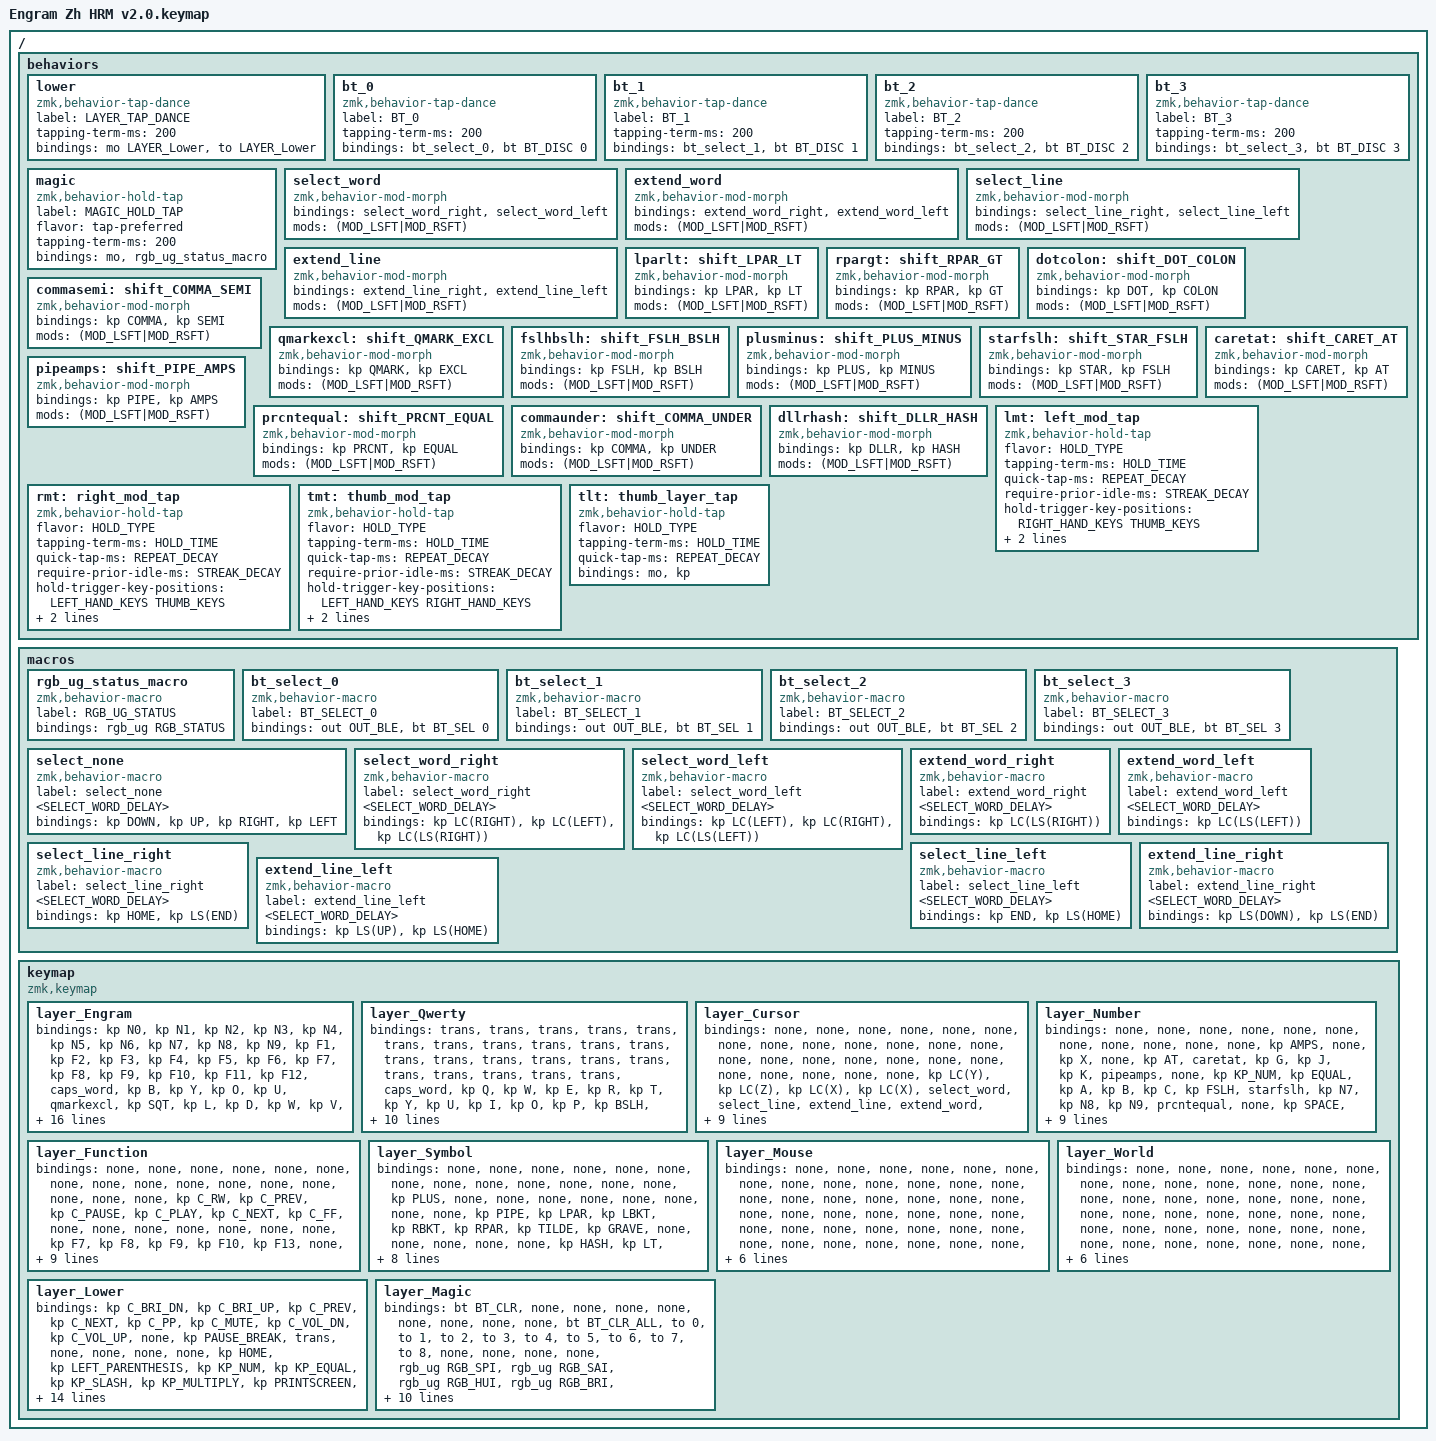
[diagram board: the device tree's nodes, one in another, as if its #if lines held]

/*
 * Copyright (c) 2020 The ZMK Contributors
 * Copyright (c) 2023 Innaworks Development Limited, trading as MoErgo
 *
 * SPDX-License-Identifier: MIT
 */


/* THIS FILE WAS GENERATED BY GLOVE80 LAYOUT EDITOR
 *
 * This file was generated automatically. You may or may not want to
 * edit it directly.
 */

#include <behaviors.dtsi>
/* Include all behavior includes needed */
#include <dt-bindings/zmk/outputs.h>
#include <dt-bindings/zmk/keys.h>
#include <dt-bindings/zmk/bt.h>
#include <dt-bindings/zmk/rgb.h>

/* Automatically generated layer name #define */
#define LAYER_Engram 0
#define LAYER_Qwerty 1
#define LAYER_Cursor 2
#define LAYER_Number 3
#define LAYER_Function 4
#define LAYER_Symbol 5
#define LAYER_Mouse 6
#define LAYER_World 7
#define LAYER_Lower 8
#define LAYER_Magic 9

/* To deal with the situation where there is no Lower layer, to keep &lower happy */
#ifndef LAYER_Lower
#define LAYER_Lower 0
#endif

/* Custom Device-tree */



/* Glove80 system behavior & macros */
/ {
    behaviors {
        // For the "layer" key, it'd nice to be able to use it as either a shift or a toggle.
        // Configure it as a tap dance, so the first tap (or hold) is a &mo and the second tap is a &to
        lower: lower {
            compatible = "zmk,behavior-tap-dance";
            label = "LAYER_TAP_DANCE";
            #binding-cells = <0>;
            tapping-term-ms = <200>;
            bindings = <&mo LAYER_Lower>, <&to LAYER_Lower>;
        };
    };
};

/ {
    macros {
        rgb_ug_status_macro: rgb_ug_status_macro {
            label = "RGB_UG_STATUS";
            compatible = "zmk,behavior-macro";
            #binding-cells = <0>;
            bindings
                = <&rgb_ug RGB_STATUS>;
        };
    };
};


/ {
#ifdef BT_DISC_CMD
    behaviors {
        bt_0: bt_0 {
            compatible = "zmk,behavior-tap-dance";
            label = "BT_0";
            #binding-cells = <0>;
            tapping-term-ms = <200>;
            bindings = <&bt_select_0>, <&bt BT_DISC 0>;
        };
        bt_1: bt_1 {
            compatible = "zmk,behavior-tap-dance";
            label = "BT_1";
            #binding-cells = <0>;
            tapping-term-ms = <200>;
            bindings = <&bt_select_1>, <&bt BT_DISC 1>;
        };
        bt_2: bt_2 {
            compatible = "zmk,behavior-tap-dance";
            label = "BT_2";
            #binding-cells = <0>;
            tapping-term-ms = <200>;
            bindings = <&bt_select_2>, <&bt BT_DISC 2>;
        };
        bt_3: bt_3 {
            compatible = "zmk,behavior-tap-dance";
            label = "BT_3";
            #binding-cells = <0>;
            tapping-term-ms = <200>;
            bindings = <&bt_select_3>, <&bt BT_DISC 3>;
        };
    };
    macros {
        bt_select_0: bt_select_0 {
            label = "BT_SELECT_0";
            compatible = "zmk,behavior-macro";
            #binding-cells = <0>;
            bindings
                = <&out OUT_BLE>,
                  <&bt BT_SEL 0>;
        };
        bt_select_1: bt_select_1 {
            label = "BT_SELECT_1";
            compatible = "zmk,behavior-macro";
            #binding-cells = <0>;
            bindings
                = <&out OUT_BLE>,
                  <&bt BT_SEL 1>;
        };
        bt_select_2: bt_select_2 {
            label = "BT_SELECT_2";
            compatible = "zmk,behavior-macro";
            #binding-cells = <0>;
            bindings
                = <&out OUT_BLE>,
                  <&bt BT_SEL 2>;
        };
        bt_select_3: bt_select_3 {
            label = "BT_SELECT_3";
            compatible = "zmk,behavior-macro";
            #binding-cells = <0>;
            bindings
                = <&out OUT_BLE>,
                  <&bt BT_SEL 3>;
        };
    };
#else
    macros {
        bt_0: bt_0 {
            label = "BT_0";
            compatible = "zmk,behavior-macro";
            #binding-cells = <0>;
            bindings
                = <&out OUT_BLE>,
                  <&bt BT_SEL 0>;
        };
        bt_1: bt_1 {
            label = "BT_1";
            compatible = "zmk,behavior-macro";
            #binding-cells = <0>;
            bindings
                = <&out OUT_BLE>,
                  <&bt BT_SEL 1>;
        };
        bt_2: bt_2 {
            label = "BT_2";
            compatible = "zmk,behavior-macro";
            #binding-cells = <0>;
            bindings
                = <&out OUT_BLE>,
                  <&bt BT_SEL 2>;
        };
        bt_3: bt_3 {
            label = "BT_3";
            compatible = "zmk,behavior-macro";
            #binding-cells = <0>;
            bindings
                = <&out OUT_BLE>,
                  <&bt BT_SEL 3>;
        };
    };
#endif
};

/ {
    behaviors {
        magic: magic {
            compatible = "zmk,behavior-hold-tap";
            label = "MAGIC_HOLD_TAP";
            #binding-cells = <2>;
            flavor = "tap-preferred";
            tapping-term-ms = <200>;
            bindings = <&mo>, <&rgb_ug_status_macro>;
        };
    };
};

/* #define for key positions */
#define POS_LH_T1 52
#define POS_LH_T2 53
#define POS_LH_T3 54
#define POS_LH_T4 69
#define POS_LH_T5 70
#define POS_LH_T6 71
#define POS_LH_C1R2 15
#define POS_LH_C1R3 27
#define POS_LH_C1R4 39
#define POS_LH_C1R5 51
#define POS_LH_C2R1 4
#define POS_LH_C2R2 14
#define POS_LH_C2R3 26
#define POS_LH_C2R4 38
#define POS_LH_C2R5 50
#define POS_LH_C2R6 68
#define POS_LH_C3R1 3
#define POS_LH_C3R2 13
#define POS_LH_C3R3 25
#define POS_LH_C3R4 37
#define POS_LH_C3R5 49
#define POS_LH_C3R6 67
#define POS_LH_C4R1 2
#define POS_LH_C4R2 12
#define POS_LH_C4R3 24
#define POS_LH_C4R4 36
#define POS_LH_C4R5 48
#define POS_LH_C4R6 66
#define POS_LH_C5R1 1
#define POS_LH_C5R2 11
#define POS_LH_C5R3 23
#define POS_LH_C5R4 35
#define POS_LH_C5R5 47
#define POS_LH_C5R6 65
#define POS_LH_C6R1 0
#define POS_LH_C6R2 10
#define POS_LH_C6R3 22
#define POS_LH_C6R4 34
#define POS_LH_C6R5 46
#define POS_LH_C6R6 64
#define POS_RH_T1 57
#define POS_RH_T2 56
#define POS_RH_T3 55
#define POS_RH_T4 74
#define POS_RH_T5 73
#define POS_RH_T6 72
#define POS_RH_C1R2 16
#define POS_RH_C1R3 28
#define POS_RH_C1R4 40
#define POS_RH_C1R5 58
#define POS_RH_C2R1 5
#define POS_RH_C2R2 17
#define POS_RH_C2R3 29
#define POS_RH_C2R4 41
#define POS_RH_C2R5 59
#define POS_RH_C2R6 75
#define POS_RH_C3R1 6
#define POS_RH_C3R2 18
#define POS_RH_C3R3 30
#define POS_RH_C3R4 42
#define POS_RH_C3R5 60
#define POS_RH_C3R6 76
#define POS_RH_C4R1 7
#define POS_RH_C4R2 19
#define POS_RH_C4R3 31
#define POS_RH_C4R4 43
#define POS_RH_C4R5 61
#define POS_RH_C4R6 77
#define POS_RH_C5R1 8
#define POS_RH_C5R2 20
#define POS_RH_C5R3 32
#define POS_RH_C5R4 44
#define POS_RH_C5R5 62
#define POS_RH_C5R6 78
#define POS_RH_C6R1 9
#define POS_RH_C6R2 21
#define POS_RH_C6R3 33
#define POS_RH_C6R4 45
#define POS_RH_C6R5 63
#define POS_RH_C6R6 79

/* Custom Defined Behaviors */
/ {
// HRM parameters
#define HOLD_TYPE "tap-preferred" // flavor of hold-tap. `tap-preferred` means modifier will only be triggered if held for `HOLD_TIME` or longer. Pressing another key before this triggers 'tap' behavior. Except for keys in `hold-trigger-key-positions`
#define HOLD_TIME 200 // how long you need to hold key in order to send their modifiers to the computer
#define STREAK_DECAY 150 // how long you need to wait after typing before you can use home row mods again.
#define REPEAT_DECAY 300 // how much time you have left after tapping a key to hold it again in order to make it auto-repeat.
#define SELECT_WORD_DELAY 1 // wait-ms and tap-ms for select word macros

// Glove80 key positions index for positional hold-tap
    #define LEFT_HAND_KEYS      \
          0  1  2  3  4         \
         10 11 12 13 14 15      \
         22 23 24 25 26 27      \
         34 35 36 37 38 39      \
         46 47 48 49 50 51      \
         64 65 66 67 68
    #define RIGHT_HAND_KEYS     \
                                           5  6  7  8  9 \
                                       16 17 18 19 20 21 \
                                       28 29 30 31 32 33 \
                                       40 41 42 43 44 45 \
                                       58 59 60 61 62 63 \
                                          75 76 77 78 79
    #define THUMB_KEYS          \
                        69 52       57 74                \
                         70 53     56 73                 \
                          71 54   55 72

macros {

    select_none: select_none {
      label = "select_none";
      compatible = "zmk,behavior-macro";
      #binding-cells = <0>;
      wait-ms: <SELECT_WORD_DELAY>;
      tap-ms: <SELECT_WORD_DELAY>;
      bindings = <&kp DOWN &kp UP &kp RIGHT &kp LEFT>;
    };

    select_word_right: select_word_right {
      label = "select_word_right";
      compatible = "zmk,behavior-macro";
      #binding-cells = <0>;
      wait-ms: <SELECT_WORD_DELAY>;
      tap-ms: <SELECT_WORD_DELAY>;
      bindings = <&kp LC(RIGHT) &kp LC(LEFT) &kp LC(LS(RIGHT))>;
    };

    select_word_left: select_word_left {
      label = "select_word_left";
      compatible = "zmk,behavior-macro";
      #binding-cells = <0>;
      wait-ms: <SELECT_WORD_DELAY>;
      tap-ms: <SELECT_WORD_DELAY>;
      bindings = <&kp LC(LEFT) &kp LC(RIGHT) &kp LC(LS(LEFT))>;
    };

    extend_word_right: extend_word_right {
      label = "extend_word_right";
      compatible = "zmk,behavior-macro";
      #binding-cells = <0>;
      wait-ms: <SELECT_WORD_DELAY>;
      tap-ms: <SELECT_WORD_DELAY>;
      bindings = <&kp LC(LS(RIGHT))>;
    };

    extend_word_left: extend_word_left {
      label = "extend_word_left";
      compatible = "zmk,behavior-macro";
      #binding-cells = <0>;
      wait-ms: <SELECT_WORD_DELAY>;
      tap-ms: <SELECT_WORD_DELAY>;
      bindings = <&kp LC(LS(LEFT))>;
    };

    select_line_right: select_line_right {
      label = "select_line_right";
      compatible = "zmk,behavior-macro";
      #binding-cells = <0>;
      wait-ms: <SELECT_WORD_DELAY>;
      tap-ms: <SELECT_WORD_DELAY>;
      bindings = <&kp HOME &kp LS(END)>;
    };

    select_line_left: select_line_left {
      label = "select_line_left";
      compatible = "zmk,behavior-macro";
      #binding-cells = <0>;
      wait-ms: <SELECT_WORD_DELAY>;
      tap-ms: <SELECT_WORD_DELAY>;
      bindings = <&kp END &kp LS(HOME)>;
    };

    extend_line_right: extend_line_right {
      label = "extend_line_right";
      compatible = "zmk,behavior-macro";
      #binding-cells = <0>;
      wait-ms: <SELECT_WORD_DELAY>;
      tap-ms: <SELECT_WORD_DELAY>;
      bindings = <&kp LS(DOWN) &kp LS(END)>;
    };

    extend_line_left: extend_line_left {
      label = "extend_line_left";
      compatible = "zmk,behavior-macro";
      #binding-cells = <0>;
      wait-ms: <SELECT_WORD_DELAY>;
      tap-ms: <SELECT_WORD_DELAY>;
      bindings = <&kp LS(UP) &kp LS(HOME)>;
    };

};

behaviors {
    select_word: select_word {
      compatible = "zmk,behavior-mod-morph";
      #binding-cells = <0>;
      bindings = <&select_word_right>, <&select_word_left>;
      mods = <(MOD_LSFT|MOD_RSFT)>;
    };

    extend_word: extend_word {
      compatible = "zmk,behavior-mod-morph";
      #binding-cells = <0>;
      bindings = <&extend_word_right>, <&extend_word_left>;
      mods = <(MOD_LSFT|MOD_RSFT)>;
    };

    select_line: select_line {
      compatible = "zmk,behavior-mod-morph";
      #binding-cells = <0>;
      bindings = <&select_line_right>, <&select_line_left>;
      mods = <(MOD_LSFT|MOD_RSFT)>;
    };

    extend_line: extend_line {
      compatible = "zmk,behavior-mod-morph";
      #binding-cells = <0>;
      bindings = <&extend_line_right>, <&extend_line_left>;
      mods = <(MOD_LSFT|MOD_RSFT)>;
    };

    lparlt: shift_LPAR_LT {
      compatible = "zmk,behavior-mod-morph";
      #binding-cells = <0>;
      bindings = <&kp LPAR>, <&kp LT>;
      mods = <(MOD_LSFT|MOD_RSFT)>;
    };

    rpargt: shift_RPAR_GT {
      compatible = "zmk,behavior-mod-morph";
      #binding-cells = <0>;
      bindings = <&kp RPAR>, <&kp GT>;
      mods = <(MOD_LSFT|MOD_RSFT)>;
    };

    dotcolon: shift_DOT_COLON {
      compatible = "zmk,behavior-mod-morph";
      #binding-cells = <0>;
      bindings = <&kp DOT>, <&kp COLON>;
      mods = <(MOD_LSFT|MOD_RSFT)>;
    };

    commasemi: shift_COMMA_SEMI {
      compatible = "zmk,behavior-mod-morph";
      #binding-cells = <0>;
      bindings = <&kp COMMA>, <&kp SEMI>;
      mods = <(MOD_LSFT|MOD_RSFT)>;
    };

    qmarkexcl: shift_QMARK_EXCL {
      compatible = "zmk,behavior-mod-morph";
      #binding-cells = <0>;
      bindings = <&kp QMARK>, <&kp EXCL>;
      mods = <(MOD_LSFT|MOD_RSFT)>;
    };

    fslhbslh: shift_FSLH_BSLH {
      compatible = "zmk,behavior-mod-morph";
      #binding-cells = <0>;
      bindings = <&kp FSLH>, <&kp BSLH>;
      mods = <(MOD_LSFT|MOD_RSFT)>;
    };

    plusminus: shift_PLUS_MINUS {
      compatible = "zmk,behavior-mod-morph";
      #binding-cells = <0>;
      bindings = <&kp PLUS>, <&kp MINUS>;
      mods = <(MOD_LSFT|MOD_RSFT)>;
    };

    starfslh: shift_STAR_FSLH {
      compatible = "zmk,behavior-mod-morph";
      #binding-cells = <0>;
      bindings = <&kp STAR>, <&kp FSLH>;
      mods = <(MOD_LSFT|MOD_RSFT)>;
    };

    caretat: shift_CARET_AT {
      compatible = "zmk,behavior-mod-morph";
      #binding-cells = <0>;
      bindings = <&kp CARET>, <&kp AT>;
      mods = <(MOD_LSFT|MOD_RSFT)>;
    };

    pipeamps: shift_PIPE_AMPS {
      compatible = "zmk,behavior-mod-morph";
      #binding-cells = <0>;
      bindings = <&kp PIPE>, <&kp AMPS>;
      mods = <(MOD_LSFT|MOD_RSFT)>;
    };

    prcntequal: shift_PRCNT_EQUAL {
      compatible = "zmk,behavior-mod-morph";
      #binding-cells = <0>;
      bindings = <&kp PRCNT>, <&kp EQUAL>;
      mods = <(MOD_LSFT|MOD_RSFT)>;
    };

    commaunder: shift_COMMA_UNDER {
      compatible = "zmk,behavior-mod-morph";
      #binding-cells = <0>;
      bindings = <&kp COMMA>, <&kp UNDER>;
      mods = <(MOD_LSFT|MOD_RSFT)>;
    };

    dllrhash: shift_DLLR_HASH {
      compatible = "zmk,behavior-mod-morph";
      #binding-cells = <0>;
      bindings = <&kp DLLR>, <&kp HASH>;
      mods = <(MOD_LSFT|MOD_RSFT)>;
    };

    lmt: left_mod_tap {
      compatible = "zmk,behavior-hold-tap";
      flavor = HOLD_TYPE;
      tapping-term-ms = <HOLD_TIME>;
      quick-tap-ms = <REPEAT_DECAY>;
      require-prior-idle-ms = <STREAK_DECAY>;
      hold-trigger-key-positions = <RIGHT_HAND_KEYS THUMB_KEYS>;
      hold-trigger-on-release; // wait for other home row mods
      #binding-cells = <2>;
      bindings = <&kp>, <&kp>;
    };

    rmt: right_mod_tap {
      compatible = "zmk,behavior-hold-tap";
      flavor = HOLD_TYPE;
      tapping-term-ms = <HOLD_TIME>;
      quick-tap-ms = <REPEAT_DECAY>;
      require-prior-idle-ms = <STREAK_DECAY>;
      hold-trigger-key-positions = <LEFT_HAND_KEYS THUMB_KEYS>;
      hold-trigger-on-release; // wait for other home row mods
      #binding-cells = <2>;
      bindings = <&kp>, <&kp>;
    };

    tmt: thumb_mod_tap {
      compatible = "zmk,behavior-hold-tap";
      flavor = HOLD_TYPE;
      tapping-term-ms = <HOLD_TIME>;
      quick-tap-ms = <REPEAT_DECAY>;
      require-prior-idle-ms = <STREAK_DECAY>;
      hold-trigger-key-positions = <LEFT_HAND_KEYS RIGHT_HAND_KEYS>;
      hold-trigger-on-release; // wait for other home row mods
      #binding-cells = <2>;
      bindings = <&kp>, <&kp>;
    };

    tlt: thumb_layer_tap {
      compatible = "zmk,behavior-hold-tap";
      flavor = HOLD_TYPE;
      tapping-term-ms = <HOLD_TIME>;
      quick-tap-ms = <REPEAT_DECAY>;
      #binding-cells = <2>;
      bindings = <&mo>, <&kp>;
    };

};
};

/* Automatically generated macro definitions */
/ {
    macros {
    
    };
};

/* Automatically generated keymap */
/ {
    keymap {
        compatible = "zmk,keymap";


        layer_Engram {
            bindings = <
               &kp N0       &kp N1       &kp N2        &kp N3                  &kp N4                                                                                                                                                                              &kp N5        &kp N6       &kp N7       &kp N8                &kp N9
               &kp F1       &kp F2       &kp F3        &kp F4                  &kp F5      &kp F6                                                                                                                                                    &kp F7        &kp F8        &kp F9      &kp F10      &kp F11               &kp F12
           &caps_word        &kp B        &kp Y         &kp O                   &kp U  &qmarkexcl                                                                                                                                                   &kp SQT         &kp L         &kp D        &kp W        &kp V              &kp CAPS
                &kp Z  &lmt LGUI C  &lmt LALT I  &lmt LCTRL E            &lmt LSHFT A  &commasemi                                                                                                                                                 &dotcolon  &rmt LSHFT H  &rmt LCTRL T  &rmt LALT S  &rmt LGUI N                 &kp Q
            &kp LSHFT        &kp G        &kp X         &kp J                   &kp K   &fslhbslh        &tmt LCTRL SPACE        &tmt LALT ENTER            &tmt LGUI TAB         &tmt RGUI ESC          &tmt RALT BSPC           &tmt RCTRL DEL  &kp MINUS         &kp R         &kp M        &kp F        &kp P        &mt RSHFT CAPS
 &magic LAYER_Magic 0     &kp LEFT       &kp UP      &kp DOWN  &tlt LAYER_Lower RIGHT              &tlt LAYER_Cursor BSPC  &tlt LAYER_Number DEL  &tlt LAYER_Function ESC  &tlt LAYER_World TAB  &tlt LAYER_Mouse ENTER  &tlt LAYER_Symbol SPACE                  &lparlt      &kp LBKT     &kp RBKT      &rpargt  &magic LAYER_Magic 0
            >;
        };

        layer_Qwerty {
            bindings = <
     &trans       &trans       &trans        &trans        &trans                                                                        &trans        &trans       &trans          &trans     &trans
     &trans       &trans       &trans        &trans        &trans  &trans                                                  &trans        &trans        &trans       &trans          &trans     &trans
 &caps_word        &kp Q        &kp W         &kp E         &kp R   &kp T                                                   &kp Y         &kp U         &kp I        &kp O           &kp P   &kp BSLH
  &kp GRAVE  &lmt LGUI A  &lmt LALT S  &lmt LCTRL D  &lmt LSHFT F   &kp G                                                   &kp H  &rmt LSHFT J  &rmt LCTRL K  &rmt LALT L  &rmt LGUI SEMI    &kp SQT
  &kp EQUAL        &kp Z        &kp X         &kp C         &kp V   &kp B  &trans  &trans  &trans  &trans  &trans  &trans   &kp N         &kp M     &kp COMMA      &kp DOT        &kp FSLH  &kp MINUS
     &trans       &trans       &trans        &trans        &trans          &trans  &trans  &trans  &trans  &trans  &trans                &trans        &trans       &trans          &trans     &trans
            >;
        };

        layer_Cursor {
            bindings = <
  &none     &none     &none      &none      &none                                                                               &none         &none         &none         &none         &none
  &none     &none     &none      &none      &none      &none                                                      &none         &none         &none         &none         &none         &none
  &none     &none     &none  &kp LC(Y)  &kp LC(Z)  &kp LC(X)                                                  &kp LC(X)  &select_word  &select_line  &extend_line  &extend_word  &select_none
  &none  &kp LGUI  &kp LALT  &kp LCTRL  &kp LSHFT  &kp LC(C)                                                  &kp LC(C)      &kp LEFT      &kp DOWN        &kp UP     &kp RIGHT     &kp LC(A)
  &none     &none     &none      &none      &none  &kp LC(V)   &none   &none   &none  &trans  &trans  &trans  &kp LC(V)      &kp HOME     &kp PG_DN     &kp PG_UP       &kp END         &none
 &trans     &none     &none      &none      &none             &tog 2   &none   &none  &trans  &trans  &trans                    &none         &none         &none         &none        &trans
            >;
        };

        layer_Number {
            bindings = <
      &none            &none        &none         &none         &none                                                                          &none   &none   &none        &none      &none
      &none         &kp AMPS        &none         &kp X         &none     &kp AT                                                    &caretat   &kp G   &kp J   &kp K    &pipeamps      &none
 &kp KP_NUM        &kp EQUAL        &kp A         &kp B         &kp C   &kp FSLH                                                   &starfslh  &kp N7  &kp N8  &kp N9  &prcntequal      &none
  &kp SPACE  &lmt LGUI UNDER  &lmt LALT D  &lmt LCTRL E  &lmt LSHFT F  &kp COLON                                                   &dotcolon  &kp N4  &kp N5  &kp N6  &commaunder  &kp SPACE
      &none         &kp HASH        &kp I         &kp J         &kp K  &kp MINUS  &trans  &trans  &trans  &trans  &trans  &trans  &plusminus  &kp N1  &kp N2  &kp N3    &dllrhash      &none
     &trans           &kp LT     &kp LBRC      &kp RBRC        &kp GT             &trans  &tog 3  &trans  &trans  &trans  &kp N0              &trans  &trans  &trans       &trans     &trans
            >;
        };

        layer_Function {
            bindings = <
  &none     &none     &none      &none      &none                                                                                             &none        &none       &none            &none     &none
  &none     &none     &none      &none      &none   &none                                                                      &kp C_RW  &kp C_PREV  &kp C_PAUSE  &kp C_PLAY       &kp C_NEXT  &kp C_FF
  &none     &none     &none      &none      &none   &none                                                                         &none      &kp F7       &kp F8      &kp F9          &kp F10   &kp F13
  &none  &kp LGUI  &kp LALT  &kp LCTRL  &kp LSHFT   &none                                                                         &none      &kp F4       &kp F5      &kp F6          &kp F11   &kp F14
  &none     &none     &none      &none      &none   &none   &none   &none   &none  &kp C_BRI_AUTO  &kp C_BRI_DN  &kp C_BRI_UP     &none      &kp F1       &kp F2      &kp F3          &kp F12   &kp F15
 &trans     &none     &none      &none      &none           &none   &none  &tog 4      &kp C_MUTE  &kp K_VOL_DN  &kp K_VOL_UP               &kp INS    &kp PSCRN    &kp SLCK  &kp PAUSE_BREAK    &trans
            >;
        };

        layer_Symbol {
            bindings = <
    &none      &none      &none      &none     &none                                                                            &none      &none     &none     &none   &none
    &none      &none      &none   &kp PLUS     &none      &none                                                      &none      &none      &none     &none     &none   &none
 &kp PIPE   &kp LPAR   &kp LBKT   &kp RBKT  &kp RPAR  &kp TILDE                                                  &kp GRAVE      &none      &none     &none     &none   &none
 &kp HASH     &kp LT  &kp EQUAL  &kp MINUS    &kp GT   &kp STAR                                                    &kp DOT  &kp LSHFT  &kp LCTRL  &kp LALT  &kp LGUI  &kp AT
 &kp AMPS  &kp CARET   &kp LBRC   &kp RBRC  &kp DLLR  &kp PRCNT  &trans  &trans  &trans   &none   &none   &none   &kp FSLH      &none      &none     &none     &none   &none
   &trans      &none      &none      &none     &none             &trans  &trans  &trans   &none   &none  &tog 5                &trans     &trans    &trans    &trans  &trans
            >;
        };

        layer_Mouse {
            bindings = <
  &none   &none   &none   &none   &none                                                                   &none   &none   &none   &none   &none
  &none   &none   &none   &none   &none   &none                                                   &none   &none   &none   &none   &none   &none
  &none   &none   &none   &none   &none   &none                                                   &none   &none   &none   &none   &none   &none
  &none   &none   &none   &none   &none   &none                                                   &none   &none   &none   &none   &none   &none
  &none   &none   &none   &none   &none   &none   &none   &none   &none   &none   &none   &none   &none   &none   &none   &none   &none   &none
 &trans   &none   &none   &none   &none           &none   &none   &none   &none   &none   &none           &none   &none   &none   &none  &trans
            >;
        };

        layer_World {
            bindings = <
  &none   &none   &none   &none   &none                                                                   &none   &none   &none   &none   &none
  &none   &none   &none   &none   &none   &none                                                   &none   &none   &none   &none   &none   &none
  &none   &none   &none   &none   &none   &none                                                   &none   &none   &none   &none   &none   &none
  &none   &none   &none   &none   &none   &none                                                   &none   &none   &none   &none   &none   &none
  &none   &none   &none   &none   &none   &none   &none   &none   &none   &none   &none   &none   &none   &none   &none   &none   &none   &none
 &trans   &none   &none   &none   &none           &none   &none   &none   &none   &none   &none           &none   &none   &none   &none  &trans
            >;
        };

        layer_Lower {
            bindings = <
 &kp C_BRI_DN  &kp C_BRI_UP      &kp C_PREV      &kp C_NEXT         &kp C_PP                                                                                    &kp C_MUTE  &kp C_VOL_DN  &kp C_VOL_UP            &none  &kp PAUSE_BREAK
       &trans         &none           &none           &none            &none   &kp HOME                                                   &kp LEFT_PARENTHESIS  &kp KP_NUM  &kp KP_EQUAL  &kp KP_SLASH  &kp KP_MULTIPLY  &kp PRINTSCREEN
       &trans         &none           &none    &kp UP_ARROW            &none    &kp END                                                  &kp RIGHT_PARENTHESIS   &kp KP_N7     &kp KP_N8     &kp KP_N9     &kp KP_MINUS   &kp SCROLLLOCK
       &trans         &none  &kp LEFT_ARROW  &kp DOWN_ARROW  &kp RIGHT_ARROW  &kp PG_UP                                                            &kp PERCENT   &kp KP_N4     &kp KP_N5     &kp KP_N6      &kp KP_PLUS            &none
       &trans     &kp K_APP           &none         &kp F11          &kp F12  &kp PG_DN  &trans  &trans  &trans  &trans  &trans  &trans              &kp COMMA   &kp KP_N1     &kp KP_N2     &kp KP_N3     &kp KP_ENTER           &trans
       &trans      &kp CAPS         &kp INS         &kp F11          &kp F12             &tog 2  &tog 3  &tog 4  &tog 7  &tog 6  &tog 5                          &kp KP_N0     &kp KP_N0    &kp KP_DOT     &kp KP_ENTER           &trans
            >;
        };

        layer_Magic {
            bindings = <
  &bt BT_CLR            &none            &none            &none            &none                                                                                  &none   &none   &none   &none  &bt BT_CLR_ALL
       &to 0            &to 1            &to 2            &to 3            &to 4            &to 5                                                         &to 6   &to 7   &to 8   &none   &none           &none
       &none  &rgb_ug RGB_SPI  &rgb_ug RGB_SAI  &rgb_ug RGB_HUI  &rgb_ug RGB_BRI  &rgb_ug RGB_TOG                                                         &none   &none   &none   &none   &none           &none
 &bootloader  &rgb_ug RGB_SPD  &rgb_ug RGB_SAD  &rgb_ug RGB_HUD  &rgb_ug RGB_BRD  &rgb_ug RGB_EFF                                                         &none   &none   &none   &none   &none     &bootloader
  &sys_reset            &none            &none            &none            &none            &none   &bt_2   &bt_3         &none   &none   &none   &none   &none   &none   &none   &none   &none      &sys_reset
       &none            &none            &none            &none            &none                    &bt_0   &bt_1  &out OUT_USB   &none   &none   &none           &none   &none   &none   &none           &none
            >;
        };

    };
};
